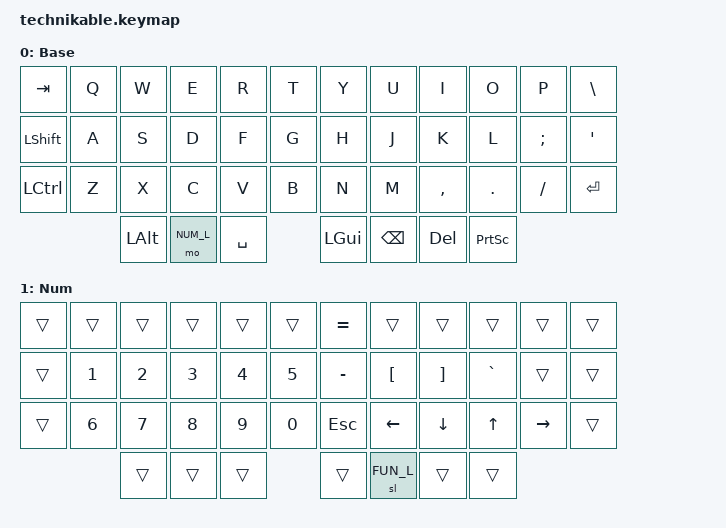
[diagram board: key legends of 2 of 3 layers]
/*
 * Copyright (c) 2022 Pete Johanson
 *
 * SPDX-License-Identifier: MIT
 */

#include <behaviors.dtsi>
#include <dt-bindings/zmk/keys.h>
#include <dt-bindings/zmk/bt.h>
#include <dt-bindings/zmk/outputs.h>

#define BAS_L 0
#define NUM_L 1
#define FUN_L 2

/ {
    chosen {
       zmk,matrix_transform = &default_transform;
    };

    keymap {
        compatible = "zmk,keymap";

        base_layer {
            label = "Base";
            bindings = <
 &kp TAB    &kp Q  &kp W     &kp E         &kp R      &kp T            &kp Y      &kp U     &kp I      &kp O      &kp P     &kp BSLH
 &kp LSHFT  &kp A  &kp S     &kp D         &kp F      &kp G            &kp H      &kp J     &kp K      &kp L      &kp SEMI  &kp QUOT
 &kp LCTRL  &kp Z  &kp X     &kp C         &kp V      &kp B            &kp N      &kp M     &kp COMMA  &kp DOT    &kp FSLH  &kp RET
                   &kp LALT  &mo NUM_L         &kp SPACE               &kp LEFT_GUI  &kp BSPC  &kp DEL    &kp PSCRN
            >;
        };

        num_layer {
            label = "Num";
            bindings = <
&trans  &trans  &trans  &trans  &trans  &trans        &kp EQUAL  &trans     &trans    &trans     &trans     &trans
&trans  &kp N1  &kp N2  &kp N3  &kp N4  &kp N5        &kp MINUS  &kp LBKT   &kp RBKT  &kp GRAVE  &trans     &trans
&trans  &kp N6  &kp N7  &kp N8  &kp N9  &kp N0        &kp ESC    &kp LEFT   &kp DOWN  &kp UP     &kp RIGHT  &trans
                &trans  &trans      &trans            &trans     &sl FUN_L  &trans    &trans
            >;
        };

        fun_layer {
            label = "Fun";
            bindings = <
&kp F1  &kp F2  &kp F3  &kp F4   &kp F5   &kp F6         &kp F13        &kp F14        &kp F15        &kp F16      &kp F17      &kp F18
&kp F7  &kp F8  &kp F9  &kp F10  &kp F11  &kp F12        &kp F19        &kp F20        &kp F21        &kp F22      &kp F23      &kp F24
&trans  &trans  &trans  &trans   &trans   &trans         &bt BT_SEL 0   &bt BT_SEL 1   &bt BT_SEL 2   &bt BT_PRV   &bt BT_NXT   &bt BT_CLR
                &trans  &trans   &trans   &trans         &trans      &trans      &trans      &trans
                &trans  &trans       &trans              &trans      &trans      &trans      &trans
            >;
        };
    };
};
